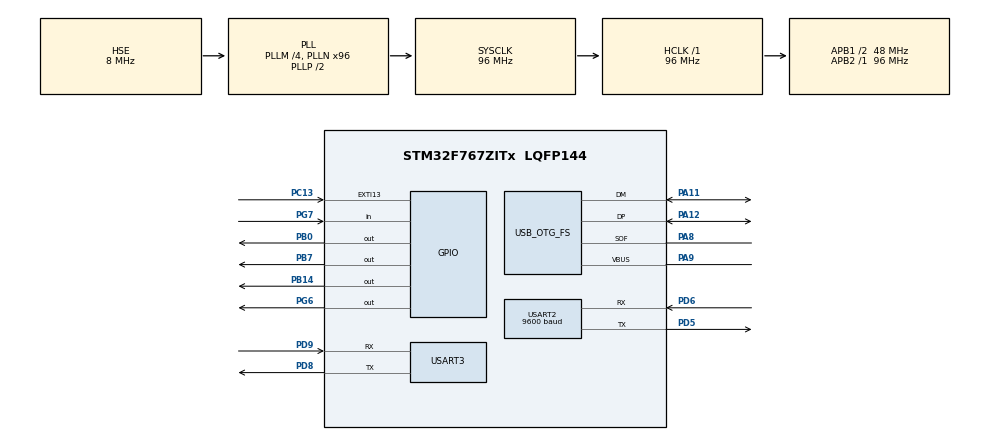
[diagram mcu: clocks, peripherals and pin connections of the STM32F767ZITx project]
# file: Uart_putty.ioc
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Mcu.Family=STM32F7
Mcu.Name=STM32F767ZITx
Mcu.Package=LQFP144
NVIC.PriorityGroup=NVIC_PRIORITYGROUP_4
NVIC.TIM2_IRQn=true\:0\:0\:false\:false\:true\:true\:true
NVIC.USART2_IRQn=true\:0\:0\:false\:false\:true\:true\:true
PA1.GPIO_Mode=GPIO_MODE_AF_PP
PA1.GPIO_PuPd=GPIO_NOPULL
PA1.GPIO_Speed=GPIO_SPEED_FREQ_VERY_HIGH
PA1.Signal=ETH_REF_CLK
PA10.GPIO_Mode=GPIO_MODE_AF_PP
PA10.GPIO_PuPd=GPIO_NOPULL
PA10.GPIO_Speed=GPIO_SPEED_FREQ_VERY_HIGH
PA10.Signal=USB_OTG_FS_ID
PA11.GPIO_Mode=GPIO_MODE_AF_PP
PA11.GPIO_PuPd=GPIO_NOPULL
PA11.GPIO_Speed=GPIO_SPEED_FREQ_VERY_HIGH
PA11.Mode=Device_Only
PA11.Signal=USB_OTG_FS_DM
PA12.GPIO_Mode=GPIO_MODE_AF_PP
PA12.GPIO_PuPd=GPIO_NOPULL
PA12.GPIO_Speed=GPIO_SPEED_FREQ_VERY_HIGH
PA12.Mode=Device_Only
PA12.Signal=USB_OTG_FS_DP
PA13.Mode=Serial_Wire
PA13.Signal=SYS_JTMS-SWDIO
PA14.Mode=Serial_Wire
PA14.Signal=SYS_JTCK-SWCLK
PA7.GPIO_Mode=GPIO_MODE_AF_PP
PA7.GPIO_PuPd=GPIO_NOPULL
PA7.GPIO_Speed=GPIO_SPEED_FREQ_VERY_HIGH
PA7.Signal=ETH_CRS_DV
PA8.GPIO_Mode=GPIO_MODE_AF_PP
PA8.GPIO_PuPd=GPIO_NOPULL
PA8.GPIO_Speed=GPIO_SPEED_FREQ_VERY_HIGH
PA8.Mode=Activate_SOF_FS
PA8.Signal=USB_OTG_FS_SOF
PA9.GPIO_Mode=GPIO_MODE_INPUT
PA9.GPIO_PuPd=GPIO_NOPULL
PA9.Mode=Activate_VBUS
PA9.Signal=USB_OTG_FS_VBUS
PB0.GPIO_ModeDefaultOutputPP=GPIO_MODE_OUTPUT_PP
PB0.GPIO_PuPd=GPIO_NOPULL
PB0.GPIO_Speed=GPIO_SPEED_FREQ_LOW
PB0.PinState=GPIO_PIN_RESET
PB0.Signal=GPIO_Output
PB13.GPIO_Mode=GPIO_MODE_AF_PP
PB13.GPIO_PuPd=GPIO_NOPULL
PB13.GPIO_Speed=GPIO_SPEED_FREQ_VERY_HIGH
PB13.Signal=ETH_TXD1
PB14.GPIO_ModeDefaultOutputPP=GPIO_MODE_OUTPUT_PP
PB14.GPIO_PuPd=GPIO_NOPULL
PB14.GPIO_Speed=GPIO_SPEED_FREQ_LOW
PB14.PinState=GPIO_PIN_RESET
PB14.Signal=GPIO_Output
PB3.Signal=SYS_JTDO-SWO
PB7.GPIO_FM7=__NULL
PB7.GPIO_ModeDefaultOutputPP=GPIO_MODE_OUTPUT_PP
PB7.GPIO_PuPd=GPIO_NOPULL
PB7.GPIO_Speed=GPIO_SPEED_FREQ_LOW
PB7.PinState=GPIO_PIN_RESET
PB7.Signal=GPIO_Output
PC1.GPIO_Mode=GPIO_MODE_AF_PP
PC1.GPIO_PuPd=GPIO_NOPULL
PC1.GPIO_Speed=GPIO_SPEED_FREQ_VERY_HIGH
PC1.Signal=ETH_MDC
PC13.GPIO_ModeDefaultEXTI=GPIO_MODE_IT_RISING
PC13.GPIO_PuPd=GPIO_NOPULL
PC13.Signal=GPXTI13
PC14/OSC32_IN.Mode=LSE-External-Oscillator
PC14/OSC32_IN.Signal=RCC_OSC32_IN
PC15/OSC32_OUT.Mode=LSE-External-Oscillator
PC15/OSC32_OUT.Signal=RCC_OSC32_OUT
PC4.GPIO_Mode=GPIO_MODE_AF_PP
PC4.GPIO_PuPd=GPIO_NOPULL
PC4.GPIO_Speed=GPIO_SPEED_FREQ_VERY_HIGH
PC4.Signal=ETH_RXD0
PC5.GPIO_Mode=GPIO_MODE_AF_PP
PC5.GPIO_PuPd=GPIO_NOPULL
PC5.GPIO_Speed=GPIO_SPEED_FREQ_VERY_HIGH
PC5.Signal=ETH_RXD1
PD5.Mode=Asynchronous
PD5.Signal=USART2_TX
PD6.Mode=Asynchronous
PD6.Signal=USART2_RX
PD8.GPIO_ModeDefaultPP=GPIO_MODE_AF_PP
PD8.GPIO_PuPd=GPIO_NOPULL
PD8.GPIO_Speed=GPIO_SPEED_FREQ_VERY_HIGH
PD8.Mode=Asynchronous
PD8.Signal=USART3_TX
PD9.GPIO_ModeDefaultPP=GPIO_MODE_AF_PP
PD9.GPIO_PuPd=GPIO_NOPULL
PD9.GPIO_Speed=GPIO_SPEED_FREQ_VERY_HIGH
PD9.Mode=Asynchronous
PD9.Signal=USART3_RX
PG11.GPIO_Mode=GPIO_MODE_AF_PP
PG11.GPIO_PuPd=GPIO_NOPULL
PG11.GPIO_Speed=GPIO_SPEED_FREQ_VERY_HIGH
PG11.Signal=ETH_TX_EN
PG13.GPIO_Mode=GPIO_MODE_AF_PP
PG13.GPIO_PuPd=GPIO_NOPULL
PG13.GPIO_Speed=GPIO_SPEED_FREQ_VERY_HIGH
PG13.Signal=ETH_TXD0
PG6.GPIO_ModeDefaultOutputPP=GPIO_MODE_OUTPUT_PP
PG6.GPIO_PuPd=GPIO_NOPULL
PG6.GPIO_Speed=GPIO_SPEED_FREQ_LOW
PG6.PinState=GPIO_PIN_RESET
PG6.Signal=GPIO_Output
PG7.GPIO_Mode=GPIO_MODE_INPUT
PG7.GPIO_PuPd=GPIO_NOPULL
PG7.Signal=GPIO_Input
PH0/OSC_IN.Mode=HSE-External-Clock-Source
PH0/OSC_IN.Signal=RCC_OSC_IN
PH1/OSC_OUT.Mode=HSE-External-Clock-Source
PH1/OSC_OUT.Signal=RCC_OSC_OUT
ProjectManager.HeapSize=0x200
ProjectManager.StackSize=0x400
ProjectManager.TargetToolchain=TrueSTUDIO
RCC.48MHZClocksFreq_Value=24000000
RCC.AHBFreq_Value=96000000
RCC.APB1CLKDivider=RCC_HCLK_DIV2
RCC.APB1Freq_Value=48000000
RCC.APB1TimFreq_Value=96000000
RCC.APB2Freq_Value=96000000
RCC.APB2TimFreq_Value=96000000
RCC.CortexFreq_Value=96000000
RCC.HCLKFreq_Value=96000000
RCC.HSE_VALUE=8000000
RCC.HSI_VALUE=16000000
RCC.PLLM=4
RCC.PLLMUL=RCC_PLL_MUL9
RCC.PLLN=96
RCC.PLLQ=4
RCC.PRESCALERUSB=RCC_USBCLKSOURCE_PLL_DIV1_5
RCC.SYSCLKFreq_VALUE=96000000
RCC.SYSCLKSource=RCC_SYSCLKSOURCE_PLLCLK
RCC.SYSCLKSourceVirtual=RCC_SYSCLKSOURCE_PLLCLK
RCC.USBFreq_Value=48000000
RCC.VCOOutputFreq_Value=192000000
TIM2.Period=1000
TIM2.Prescaler=16000
USART2.BaudRate=9600
USART2.Mode=MODE_TX_RX
USART2.VirtualMode-Asynchronous=VM_ASYNC
USART2.WordLength=WORDLENGTH_8B
USART3.VirtualMode-Asynchronous=VM_ASYNC
USB_OTG_FS.VirtualMode=Device_Only
VP_TIM2_VS_ClockSourceINT.Mode=Internal
board=NUCLEO-F767ZI

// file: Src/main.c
/* USER CODE BEGIN Header */
/**
  ******************************************************************************
  * @file           : main.c
  * @brief          : Main program body
  ******************************************************************************
  * @attention
  *
  * <h2><center>&copy; Copyright (c) 2019 STMicroelectronics.
  * All rights reserved.</center></h2>
  *
  * This software component is licensed by ST under BSD 3-Clause license,
  * the "License"; You may not use this file except in compliance with the
  * License. You may obtain a copy of the License at:
  *                        opensource.org/licenses/BSD-3-Clause
  *
  ******************************************************************************
  */
/* USER CODE END Header */

#include "main.h"

TIM_HandleTypeDef htim2;

UART_HandleTypeDef huart2;
UART_HandleTypeDef huart3;

PCD_HandleTypeDef hpcd_USB_OTG_FS;

void SystemClock_Config(void);
static void MX_GPIO_Init(void);
static void MX_USART3_UART_Init(void);
static void MX_USB_OTG_FS_PCD_Init(void);
static void MX_TIM2_Init(void);
static void MX_USART2_UART_Init(void);

/* USER CODE BEGIN 0 */
//uint8_t data[10];
uint8_t datal[]= "Voici ce ke je send\n";

/* USER CODE END 0 */

int main(void)
{

  /* MCU Configuration--------------------------------------------------------*/

  /* Reset of all peripherals, Initializes the Flash interface and the Systick. */
  HAL_Init();

  /* Configure the system clock */
  SystemClock_Config();

  /* Initialize all configured peripherals */
  MX_GPIO_Init();
  MX_USART3_UART_Init();
  MX_USB_OTG_FS_PCD_Init();
  MX_TIM2_Init();
  MX_USART2_UART_Init();

  /* Infinite loop */
  while (1)
  {

    /* USER CODE BEGIN 3 */

	  //HAL_UART_Receive(&huart2, data,10,1000);
	  HAL_UART_Transmit(&huart2, datal,sizeof(datal),1000);
	  HAL_Delay(500);
  }
  /* USER CODE END 3 */
}

void SystemClock_Config(void)
{
  RCC_OscInitTypeDef RCC_OscInitStruct = {0};
  RCC_ClkInitTypeDef RCC_ClkInitStruct = {0};
  RCC_PeriphCLKInitTypeDef PeriphClkInitStruct = {0};

  /** Configure LSE Drive Capability
  */
  HAL_PWR_EnableBkUpAccess();
  /** Configure the main internal regulator output voltage
  */
  __HAL_RCC_PWR_CLK_ENABLE();
  __HAL_PWR_VOLTAGESCALING_CONFIG(PWR_REGULATOR_VOLTAGE_SCALE3);
  /** Initializes the CPU, AHB and APB busses clocks
  */
  RCC_OscInitStruct.OscillatorType = RCC_OSCILLATORTYPE_HSE;
  RCC_OscInitStruct.HSEState = RCC_HSE_BYPASS;
  RCC_OscInitStruct.PLL.PLLState = RCC_PLL_ON;
  RCC_OscInitStruct.PLL.PLLSource = RCC_PLLSOURCE_HSE;
  RCC_OscInitStruct.PLL.PLLM = 4;
  RCC_OscInitStruct.PLL.PLLN = 96;
  RCC_OscInitStruct.PLL.PLLP = RCC_PLLP_DIV2;
  RCC_OscInitStruct.PLL.PLLQ = 4;
  if (HAL_RCC_OscConfig(&RCC_OscInitStruct) != HAL_OK)
  {
    Error_Handler();
  }
  /** Activate the Over-Drive mode
  */
  if (HAL_PWREx_EnableOverDrive() != HAL_OK)
  {
    Error_Handler();
  }
  /** Initializes the CPU, AHB and APB busses clocks
  */
  RCC_ClkInitStruct.ClockType = RCC_CLOCKTYPE_HCLK|RCC_CLOCKTYPE_SYSCLK
                              |RCC_CLOCKTYPE_PCLK1|RCC_CLOCKTYPE_PCLK2;
  RCC_ClkInitStruct.SYSCLKSource = RCC_SYSCLKSOURCE_PLLCLK;
  RCC_ClkInitStruct.AHBCLKDivider = RCC_SYSCLK_DIV1;
  RCC_ClkInitStruct.APB1CLKDivider = RCC_HCLK_DIV2;
  RCC_ClkInitStruct.APB2CLKDivider = RCC_HCLK_DIV1;

  if (HAL_RCC_ClockConfig(&RCC_ClkInitStruct, FLASH_LATENCY_3) != HAL_OK)
  {
    Error_Handler();
  }
  PeriphClkInitStruct.PeriphClockSelection = RCC_PERIPHCLK_USART2|RCC_PERIPHCLK_USART3
                              |RCC_PERIPHCLK_CLK48;
  PeriphClkInitStruct.Usart2ClockSelection = RCC_USART2CLKSOURCE_PCLK1;
  PeriphClkInitStruct.Usart3ClockSelection = RCC_USART3CLKSOURCE_PCLK1;
  PeriphClkInitStruct.Clk48ClockSelection = RCC_CLK48SOURCE_PLL;
  if (HAL_RCCEx_PeriphCLKConfig(&PeriphClkInitStruct) != HAL_OK)
  {
    Error_Handler();
  }
}

static void MX_TIM2_Init(void)
{

  TIM_ClockConfigTypeDef sClockSourceConfig = {0};
  TIM_MasterConfigTypeDef sMasterConfig = {0};

  htim2.Instance = TIM2;
  htim2.Init.Prescaler = 16000;
  htim2.Init.CounterMode = TIM_COUNTERMODE_UP;
  htim2.Init.Period = 1000;
  htim2.Init.ClockDivision = TIM_CLOCKDIVISION_DIV1;
  htim2.Init.AutoReloadPreload = TIM_AUTORELOAD_PRELOAD_DISABLE;
  if (HAL_TIM_Base_Init(&htim2) != HAL_OK)
  {
    Error_Handler();
  }
  sClockSourceConfig.ClockSource = TIM_CLOCKSOURCE_INTERNAL;
  if (HAL_TIM_ConfigClockSource(&htim2, &sClockSourceConfig) != HAL_OK)
  {
    Error_Handler();
  }
  sMasterConfig.MasterOutputTrigger = TIM_TRGO_RESET;
  sMasterConfig.MasterSlaveMode = TIM_MASTERSLAVEMODE_DISABLE;
  if (HAL_TIMEx_MasterConfigSynchronization(&htim2, &sMasterConfig) != HAL_OK)
  {
    Error_Handler();
  }

}

static void MX_USART2_UART_Init(void)
{

  huart2.Instance = USART2;
  huart2.Init.BaudRate = 9600;
  huart2.Init.WordLength = UART_WORDLENGTH_8B;
  huart2.Init.StopBits = UART_STOPBITS_1;
  huart2.Init.Parity = UART_PARITY_NONE;
  huart2.Init.Mode = UART_MODE_TX_RX;
  huart2.Init.HwFlowCtl = UART_HWCONTROL_NONE;
  huart2.Init.OverSampling = UART_OVERSAMPLING_16;
  huart2.Init.OneBitSampling = UART_ONE_BIT_SAMPLE_DISABLE;
  huart2.AdvancedInit.AdvFeatureInit = UART_ADVFEATURE_NO_INIT;
  if (HAL_UART_Init(&huart2) != HAL_OK)
  {
    Error_Handler();
  }

}

static void MX_USART3_UART_Init(void)
{

  huart3.Instance = USART3;
  huart3.Init.BaudRate = 115200;
  huart3.Init.WordLength = UART_WORDLENGTH_8B;
  huart3.Init.StopBits = UART_STOPBITS_1;
  huart3.Init.Parity = UART_PARITY_NONE;
  huart3.Init.Mode = UART_MODE_TX_RX;
  huart3.Init.HwFlowCtl = UART_HWCONTROL_NONE;
  huart3.Init.OverSampling = UART_OVERSAMPLING_16;
  huart3.Init.OneBitSampling = UART_ONE_BIT_SAMPLE_DISABLE;
  huart3.AdvancedInit.AdvFeatureInit = UART_ADVFEATURE_NO_INIT;
  if (HAL_UART_Init(&huart3) != HAL_OK)
  {
    Error_Handler();
  }

}

static void MX_USB_OTG_FS_PCD_Init(void)
{

  hpcd_USB_OTG_FS.Instance = USB_OTG_FS;
  hpcd_USB_OTG_FS.Init.dev_endpoints = 6;
  hpcd_USB_OTG_FS.Init.speed = PCD_SPEED_FULL;
  hpcd_USB_OTG_FS.Init.dma_enable = DISABLE;
  hpcd_USB_OTG_FS.Init.phy_itface = PCD_PHY_EMBEDDED;
  hpcd_USB_OTG_FS.Init.Sof_enable = ENABLE;
  hpcd_USB_OTG_FS.Init.low_power_enable = DISABLE;
  hpcd_USB_OTG_FS.Init.lpm_enable = DISABLE;
  hpcd_USB_OTG_FS.Init.vbus_sensing_enable = ENABLE;
  hpcd_USB_OTG_FS.Init.use_dedicated_ep1 = DISABLE;
  if (HAL_PCD_Init(&hpcd_USB_OTG_FS) != HAL_OK)
  {
    Error_Handler();
  }

}

static void MX_GPIO_Init(void)
{
  GPIO_InitTypeDef GPIO_InitStruct = {0};

  /* GPIO Ports Clock Enable */
  __HAL_RCC_GPIOC_CLK_ENABLE();
  __HAL_RCC_GPIOH_CLK_ENABLE();
  __HAL_RCC_GPIOA_CLK_ENABLE();
  __HAL_RCC_GPIOB_CLK_ENABLE();
  __HAL_RCC_GPIOD_CLK_ENABLE();
  __HAL_RCC_GPIOG_CLK_ENABLE();

  /*Configure GPIO pin Output Level */
  HAL_GPIO_WritePin(GPIOB, GPIO_PIN_0|GPIO_PIN_14|GPIO_PIN_7, GPIO_PIN_RESET);

  /*Configure GPIO pin Output Level */
  HAL_GPIO_WritePin(GPIOG, GPIO_PIN_6, GPIO_PIN_RESET);

  /*Configure GPIO pin : PC13 */
  GPIO_InitStruct.Pin = GPIO_PIN_13;
  GPIO_InitStruct.Mode = GPIO_MODE_IT_RISING;
  GPIO_InitStruct.Pull = GPIO_NOPULL;
  HAL_GPIO_Init(GPIOC, &GPIO_InitStruct);

  /*Configure GPIO pins : PC1 PC4 PC5 */
  GPIO_InitStruct.Pin = GPIO_PIN_1|GPIO_PIN_4|GPIO_PIN_5;
  GPIO_InitStruct.Mode = GPIO_MODE_AF_PP;
  GPIO_InitStruct.Pull = GPIO_NOPULL;
  GPIO_InitStruct.Speed = GPIO_SPEED_FREQ_VERY_HIGH;
  GPIO_InitStruct.Alternate = GPIO_AF11_ETH;
  HAL_GPIO_Init(GPIOC, &GPIO_InitStruct);

  /*Configure GPIO pins : PA1 PA7 */
  GPIO_InitStruct.Pin = GPIO_PIN_1|GPIO_PIN_7;
  GPIO_InitStruct.Mode = GPIO_MODE_AF_PP;
  GPIO_InitStruct.Pull = GPIO_NOPULL;
  GPIO_InitStruct.Speed = GPIO_SPEED_FREQ_VERY_HIGH;
  GPIO_InitStruct.Alternate = GPIO_AF11_ETH;
  HAL_GPIO_Init(GPIOA, &GPIO_InitStruct);

  /*Configure GPIO pins : PB0 PB14 PB7 */
  GPIO_InitStruct.Pin = GPIO_PIN_0|GPIO_PIN_14|GPIO_PIN_7;
  GPIO_InitStruct.Mode = GPIO_MODE_OUTPUT_PP;
  GPIO_InitStruct.Pull = GPIO_NOPULL;
  GPIO_InitStruct.Speed = GPIO_SPEED_FREQ_LOW;
  HAL_GPIO_Init(GPIOB, &GPIO_InitStruct);

  /*Configure GPIO pin : PB13 */
  GPIO_InitStruct.Pin = GPIO_PIN_13;
  GPIO_InitStruct.Mode = GPIO_MODE_AF_PP;
  GPIO_InitStruct.Pull = GPIO_NOPULL;
  GPIO_InitStruct.Speed = GPIO_SPEED_FREQ_VERY_HIGH;
  GPIO_InitStruct.Alternate = GPIO_AF11_ETH;
  HAL_GPIO_Init(GPIOB, &GPIO_InitStruct);

  /*Configure GPIO pin : PG6 */
  GPIO_InitStruct.Pin = GPIO_PIN_6;
  GPIO_InitStruct.Mode = GPIO_MODE_OUTPUT_PP;
  GPIO_InitStruct.Pull = GPIO_NOPULL;
  GPIO_InitStruct.Speed = GPIO_SPEED_FREQ_LOW;
  HAL_GPIO_Init(GPIOG, &GPIO_InitStruct);

  /*Configure GPIO pin : PG7 */
  GPIO_InitStruct.Pin = GPIO_PIN_7;
  GPIO_InitStruct.Mode = GPIO_MODE_INPUT;
  GPIO_InitStruct.Pull = GPIO_NOPULL;
  HAL_GPIO_Init(GPIOG, &GPIO_InitStruct);

  /*Configure GPIO pins : PG11 PG13 */
  GPIO_InitStruct.Pin = GPIO_PIN_11|GPIO_PIN_13;
  GPIO_InitStruct.Mode = GPIO_MODE_AF_PP;
  GPIO_InitStruct.Pull = GPIO_NOPULL;
  GPIO_InitStruct.Speed = GPIO_SPEED_FREQ_VERY_HIGH;
  GPIO_InitStruct.Alternate = GPIO_AF11_ETH;
  HAL_GPIO_Init(GPIOG, &GPIO_InitStruct);

}

void Error_Handler(void)
{
}

/************************ (C) COPYRIGHT STMicroelectronics *****END OF FILE****/
